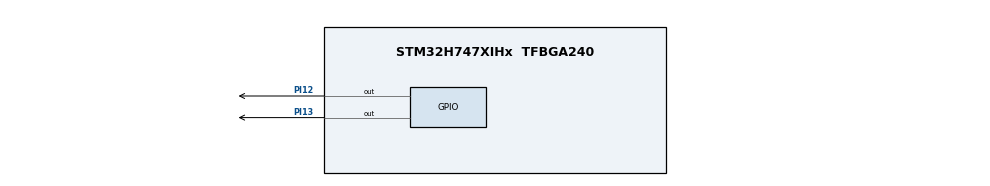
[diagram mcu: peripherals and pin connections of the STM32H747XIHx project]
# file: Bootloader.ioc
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CortexM4.IPs=BDMA,CORTEX_M4\:I,DEBUG,DMA,FATFS_M4\:I,FREERTOS_M4\:I,IWDG2\:I,MDMA,NVIC2\:I,OPENAMP_M4\:I,PDM2PCM_M4\:I,PWR,RCC,RESMGR_UTILITY,SYS_M4\:I,USB_DEVICE_M4\:I,USB_HOST_M4\:I,VREFBUF,WWDG2\:I
CortexM7.IPs=BDMA\:I,CORTEX_M7\:I,DEBUG\:I,DMA\:I,FATFS_M7\:I,FREERTOS_M7\:I,IWDG1\:I,MDMA\:I,NVIC1\:I,OPENAMP_M7\:I,PDM2PCM_M7\:I,PWR\:I,RCC\:I,RESMGR_UTILITY\:I,SYS\:I,USB_DEVICE_M7\:I,USB_HOST_M7\:I,VREFBUF\:I,WWDG1\:I
CortexM7.Pins=PI12,PI13
Mcu.Family=STM32H7
Mcu.Name=STM32H747XIHx
Mcu.Package=TFBGA240
NVIC1.PriorityGroup=NVIC_PRIORITYGROUP_4
NVIC2.PriorityGroup=NVIC_PRIORITYGROUP_4
PI12.GPIO_ModeDefaultOutputPP=GPIO_MODE_OUTPUT_PP
PI12.PinAttribute=CortexM7
PI12.PinState=GPIO_PIN_RESET
PI12.Signal=GPIO_Output
PI13.GPIO_ModeDefaultOutputPP=GPIO_MODE_OUTPUT_PP
PI13.PinAttribute=CortexM7
PI13.PinState=GPIO_PIN_RESET
PI13.Signal=GPIO_Output
ProjectManager.HeapSize=M4-0x200,M7-0x200
ProjectManager.StackSize=M4-0x400,M7-0x400
ProjectManager.TargetToolchain=STM32CubeIDE
RCC.ADCFreq_Value=129000000
RCC.APB1Freq_Value=64000000
RCC.APB2Freq_Value=64000000
RCC.APB3Freq_Value=64000000
RCC.APB4Freq_Value=64000000
RCC.CortexFreq_Value=64000000
RCC.HCLKFreq_Value=64000000
RCC.SYSCLKFreq_VALUE=64000000
RCC.USBFreq_Value=129000000
SYS.userName=SYS_M7
VP_SYS_M4_VS_Systick.Mode=SysTick
board=custom

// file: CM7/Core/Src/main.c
/* USER CODE BEGIN Header */
/**
  ******************************************************************************
  * @file           : main.c
  * @brief          : Main program body
  ******************************************************************************
  * @attention
  *
  * Copyright (c) 2022 STMicroelectronics.
  * All rights reserved.
  *
  * This software is licensed under terms that can be found in the LICENSE file
  * in the root directory of this software component.
  * If no LICENSE file comes with this software, it is provided AS-IS.
  *
  ******************************************************************************
  */
/* USER CODE END Header */
#include "main.h"

/* USER CODE BEGIN PD */

#ifndef HSEM_ID_0
#define HSEM_ID_0 (0U) /* HW semaphore 0*/
#endif
/* USER CODE END PD */

void SystemClock_Config(void);
static void MX_GPIO_Init(void);
/* USER CODE BEGIN PFP */
uint16_t x=0;
/* USER CODE END PFP */

int main(void)
{
/* USER CODE BEGIN Boot_Mode_Sequence_0 */
  int32_t timeout;
/* USER CODE END Boot_Mode_Sequence_0 */

/* USER CODE BEGIN Boot_Mode_Sequence_1 */
  /* Wait until CPU2 boots and enters in stop mode or timeout*/
  timeout = 0xFFFF;
  while((__HAL_RCC_GET_FLAG(RCC_FLAG_D2CKRDY) != RESET) && (timeout-- > 0));
  if ( timeout < 0 )
  {
  Error_Handler();
  }
/* USER CODE END Boot_Mode_Sequence_1 */
  /* MCU Configuration--------------------------------------------------------*/

  /* Reset of all peripherals, Initializes the Flash interface and the Systick. */
  HAL_Init();

  /* Configure the system clock */
  SystemClock_Config();
/* USER CODE BEGIN Boot_Mode_Sequence_2 */
/* When system initialization is finished, Cortex-M7 will release Cortex-M4 by means of
HSEM notification */
/*HW semaphore Clock enable*/
__HAL_RCC_HSEM_CLK_ENABLE();
/*Take HSEM */
HAL_HSEM_FastTake(HSEM_ID_0);
/*Release HSEM in order to notify the CPU2(CM4)*/
HAL_HSEM_Release(HSEM_ID_0,0);
/* wait until CPU2 wakes up from stop mode */
timeout = 0xFFFF;
while((__HAL_RCC_GET_FLAG(RCC_FLAG_D2CKRDY) == RESET) && (timeout-- > 0));
if ( timeout < 0 )
{
Error_Handler();
}
/* USER CODE END Boot_Mode_Sequence_2 */

  /* Initialize all configured peripherals */
  MX_GPIO_Init();

  /* Infinite loop */
  while (1)
  {

    /* USER CODE BEGIN 3 */
	  x++;

  }
  /* USER CODE END 3 */
}

void SystemClock_Config(void)
{
  RCC_OscInitTypeDef RCC_OscInitStruct = {0};
  RCC_ClkInitTypeDef RCC_ClkInitStruct = {0};

  /** Supply configuration update enable
  */
  HAL_PWREx_ConfigSupply(PWR_DIRECT_SMPS_SUPPLY);
  /** Configure the main internal regulator output voltage
  */
  __HAL_PWR_VOLTAGESCALING_CONFIG(PWR_REGULATOR_VOLTAGE_SCALE3);

  while(!__HAL_PWR_GET_FLAG(PWR_FLAG_VOSRDY)) {}
  /** Initializes the RCC Oscillators according to the specified parameters
  * in the RCC_OscInitTypeDef structure.
  */
  RCC_OscInitStruct.OscillatorType = RCC_OSCILLATORTYPE_HSI;
  RCC_OscInitStruct.HSIState = RCC_HSI_DIV1;
  RCC_OscInitStruct.HSICalibrationValue = RCC_HSICALIBRATION_DEFAULT;
  RCC_OscInitStruct.PLL.PLLState = RCC_PLL_NONE;
  if (HAL_RCC_OscConfig(&RCC_OscInitStruct) != HAL_OK)
  {
    Error_Handler();
  }
  /** Initializes the CPU, AHB and APB buses clocks
  */
  RCC_ClkInitStruct.ClockType = RCC_CLOCKTYPE_HCLK|RCC_CLOCKTYPE_SYSCLK
                              |RCC_CLOCKTYPE_PCLK1|RCC_CLOCKTYPE_PCLK2
                              |RCC_CLOCKTYPE_D3PCLK1|RCC_CLOCKTYPE_D1PCLK1;
  RCC_ClkInitStruct.SYSCLKSource = RCC_SYSCLKSOURCE_HSI;
  RCC_ClkInitStruct.SYSCLKDivider = RCC_SYSCLK_DIV1;
  RCC_ClkInitStruct.AHBCLKDivider = RCC_HCLK_DIV1;
  RCC_ClkInitStruct.APB3CLKDivider = RCC_APB3_DIV1;
  RCC_ClkInitStruct.APB1CLKDivider = RCC_APB1_DIV1;
  RCC_ClkInitStruct.APB2CLKDivider = RCC_APB2_DIV1;
  RCC_ClkInitStruct.APB4CLKDivider = RCC_APB4_DIV1;

  if (HAL_RCC_ClockConfig(&RCC_ClkInitStruct, FLASH_LATENCY_1) != HAL_OK)
  {
    Error_Handler();
  }
}

static void MX_GPIO_Init(void)
{
  GPIO_InitTypeDef GPIO_InitStruct = {0};

  /* GPIO Ports Clock Enable */
  __HAL_RCC_GPIOI_CLK_ENABLE();

  /*Configure GPIO pin Output Level */
  HAL_GPIO_WritePin(GPIOI, GPIO_PIN_12|GPIO_PIN_13, GPIO_PIN_RESET);

  /*Configure GPIO pins : PI12 PI13 */

}

void Error_Handler(void)
{
  __disable_irq();
  while (1)
  {
  }
}
